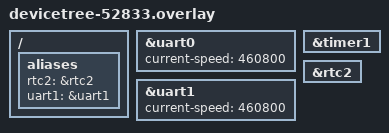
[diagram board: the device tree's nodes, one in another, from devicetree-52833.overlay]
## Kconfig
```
#
# Copyright (c) 2020 Nordic Semiconductor
#
# SPDX-License-Identifier: LicenseRef-Nordic-5-Clause
#

source "Kconfig.zephyr"

menu "Nordic Bluetooth Mesh chat client sample"

config DEVICE_IS_MASTER
    bool "Device is master"
    default n
    help
      Set to y if this device should act as the master device.
	  
config BT_MESH_CHAT_CLI_MESSAGE_LENGTH
	int "Max length of the message to be sent over mesh"
	default 90
	range 0 255
	help
	  Impacts on memory size occupied by the buffer of a message to be
	  published. This does not include null terminator. The message must also
	  fit into the application SDU. Adjust BT_MESH_TX_SEG_MAX and
	  BT_MESH_RX_SEG_MAX to be able to receive the longest messages.

config BT_MESH_CHAT_SAMPLE_PRESENCE_CACHE_SIZE
	int "Presence cache size"
	default 10
	range 0 32767
	help
	  Presence cache stores previously received presence of chat clients.
	  Recommended to be as big as number of chat clients in the mesh network.

config COUNTER_SAM0_TC32
	bool
	default y if BOARD_ATSAMD20_XPRO

endmenu

module = BT_MESH_CHAT_CLI
module-str = BT Mesh Chat Client model
source "${ZEPHYR_BASE}/subsys/logging/Kconfig.template.log_config"
```

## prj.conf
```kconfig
#
# Copyright (c) 2020 Nordic Semiconductor ASA
#
# SPDX-License-Identifier: LicenseRef-Nordic-5-Clause
#
CONFIG_NCS_SAMPLES_DEFAULTS=y

# Deffered logging helps improve LPN power consumption
# when friendship is established.
CONFIG_LOG_MODE_DEFERRED=y

# General configuration
CONFIG_SYSTEM_WORKQUEUE_STACK_SIZE=2048
CONFIG_FLASH=y
CONFIG_FLASH_MAP=y
CONFIG_NVS=y
CONFIG_SETTINGS=y
CONFIG_NVS_LOOKUP_CACHE=y
CONFIG_SETTINGS_NVS_NAME_CACHE=y
CONFIG_HWINFO=y
CONFIG_DK_LIBRARY=y
CONFIG_PM_SINGLE_IMAGE=y
CONFIG_PM_PARTITION_SIZE_SETTINGS_STORAGE=0x8000
CONFIG_SOC_FLASH_NRF_PARTIAL_ERASE=y

# Bluetooth configuration
CONFIG_BT=y
CONFIG_BT_DEVICE_NAME="Mesh Chat"
CONFIG_BT_L2CAP_TX_BUF_COUNT=8
CONFIG_BT_OBSERVER=y
CONFIG_BT_PERIPHERAL=y
CONFIG_BT_SETTINGS=y

# Disable unused Bluetooth features
CONFIG_BT_CTLR_LE_ENC=n
CONFIG_BT_PHY_UPDATE=n
CONFIG_BT_CTLR_CHAN_SEL_2=n
CONFIG_BT_CTLR_MIN_USED_CHAN=n
CONFIG_BT_CTLR_PRIVACY=n

# Bluetooth Mesh configuration
CONFIG_BT_MESH=y
CONFIG_BT_MESH_RELAY=y
CONFIG_BT_MESH_FRIEND=y
CONFIG_BT_MESH_RX_SEG_MAX=10
CONFIG_BT_MESH_TX_SEG_MAX=10
CONFIG_BT_MESH_PB_GATT=y
CONFIG_BT_MESH_GATT_PROXY=y
CONFIG_BT_MESH_DK_PROV=y

CONFIG_BT_MESH_TX_SEG_MSG_COUNT=5
CONFIG_BT_MESH_RX_SEG_MSG_COUNT=5
CONFIG_BT_MESH_CHAT_CLI_MESSAGE_LENGTH=70
CONFIG_BT_MESH_ADV_BUF_COUNT= 20
#CONFIG_BT_MESH_SEG_BUFS=1024


# Enable Bluetooth Mesh models debug logs
CONFIG_BT_MESH_LOG_LEVEL_ERR=y

# Enable Shell module and use UART as a backend
CONFIG_SHELL=y
CONFIG_SHELL_BACKEND_SERIAL=y
CONFIG_FLASH_SHELL=n
# Enable RTT for logging
CONFIG_USE_SEGGER_RTT=y
CONFIG_RTT_CONSOLE=y

# Enable logging
CONFIG_LOG=y
CONFIG_LOG_DEFAULT_LEVEL=3
CONFIG_LOG_BACKEND_RTT=y
CONFIG_LOG_BACKEND_UART=n

# Enable BT scan
CONFIG_BT_SCAN=y
# CONFIG_BT_SCAN_FILTER_ENABLE=y
CONFIG_BT_SCAN_UUID_CNT=20

CONFIG_BT_CTLR_TX_PWR_PLUS_8=y
```

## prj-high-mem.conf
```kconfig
# #
# # Copyright (c) 2020 Nordic Semiconductor ASA
# #
# # SPDX-License-Identifier: LicenseRef-Nordic-5-Clause
# #

# # MASTER device
# CONFIG_DEVICE_IS_MASTER=y

# CONFIG_NCS_SAMPLES_DEFAULTS=y

# # Deffered logging helps improve LPN power consumption
# # when friendship is established.
# CONFIG_LOG_MODE_DEFERRED=y

# # General configuration
# CONFIG_SYSTEM_WORKQUEUE_STACK_SIZE=2048
# CONFIG_FLASH=y
# CONFIG_FLASH_MAP=y
# CONFIG_NVS=y
# CONFIG_SETTINGS=y
# CONFIG_NVS_LOOKUP_CACHE=y
# CONFIG_SETTINGS_NVS_NAME_CACHE=y
# CONFIG_HWINFO=y
# CONFIG_DK_LIBRARY=y
# CONFIG_PM_SINGLE_IMAGE=y
# CONFIG_PM_PARTITION_SIZE_SETTINGS_STORAGE=0x8000
# CONFIG_SOC_FLASH_NRF_PARTIAL_ERASE=y

# # Bluetooth configuration
# CONFIG_BT=y
# CONFIG_BT_DEVICE_NAME="Mesh Chat"
# CONFIG_BT_L2CAP_TX_BUF_COUNT=8
# CONFIG_BT_OBSERVER=y
# CONFIG_BT_PERIPHERAL=y
# CONFIG_BT_SETTINGS=y
# CONFIG_BT_EXT_ADV=y

# # 5 sets are used by Bluetooth Mesh, 1 is needed for the sample advs.
# CONFIG_BT_EXT_ADV_MAX_ADV_SET=6
# CONFIG_BT_MAX_CONN=3
# CONFIG_BT_ID_MAX=2

# # Disable unused Bluetooth features
# # CONFIG_BT_CTLR_LE_ENC=n
# # CONFIG_BT_PHY_UPDATE=n
# # CONFIG_BT_CTLR_CHAN_SEL_2=n
# # CONFIG_BT_CTLR_MIN_USED_CHAN=n
# # CONFIG_BT_CTLR_PRIVACY=n

# # Bluetooth Mesh configuration
# CONFIG_BT_MESH=y
# CONFIG_BT_MESH_RELAY=y
# CONFIG_BT_MESH_FRIEND=y
# CONFIG_BT_MESH_RX_SEG_MAX=10
# CONFIG_BT_MESH_TX_SEG_MAX=10
# CONFIG_BT_MESH_PB_GATT=y
# CONFIG_BT_MESH_GATT_PROXY=y
# CONFIG_BT_MESH_DK_PROV=y
# CONFIG_BT_MESH_PB_ADV=y
# CONFIG_BT_MESH_CFG_CLI=y
# CONFIG_BT_MESH_MODEL_GROUP_COUNT=2

# # Enable Bluetooth Mesh models debug logs
# CONFIG_BT_MESH_LOG_LEVEL_DBG=y
# CONFIG_LOG=y
# CONFIG_LOG_DEFAULT_LEVEL=3
# CONFIG_UART_CONSOLE=n
# CONFIG_UART_LINE_CTRL=n


# # Enable Shell module and use UART as a backend
# CONFIG_SHELL=y
# CONFIG_SHELL_BACKEND_SERIAL=y
# CONFIG_FLASH_SHELL=n



# # RTT console 

# CONFIG_USE_SEGGER_RTT=y
# CONFIG_RTT_CONSOLE=y
# CONFIG_LOG_BACKEND_RTT=y
# CONFIG_LOG_BACKEND_UART=n
# CONFIG_SEGGER_RTT_MODE_NO_BLOCK_SKIP=y


# CONFIG_U_BT_NUS_CLIENT=y
# # CONFIG_BT_SCAN_FILTER_ENABLE=y
# # CONFIG_BT_GATT_DM=y
# # CONFIG_HEAP_MEM_POOL_SIZE=2048

# # # This example requires more stack
# # CONFIG_MAIN_STACK_SIZE=1536

# # # Enable bonding
# # CONFIG_FLASH_PAGE_LAYOUT=y

# # # Enable UART line control API
# # CONFIG_UART_LINE_CTRL=y
# # CONFIG_LOG_DEFAULT_LEVEL=4

# # CONFIG_ASSERT=y

# ART_INTERRUPT_DRIVEN=y
# CONFIG_COUNTER=y

# # Copyright (c) 2018 Nordic Semiconductor
# #
# # SPDX-License-Identifier: LicenseRef-Nordic-5-Clause
# #


# # Enable the BLE stack with GATT Client configuration
# CONFIG_BT_SMP=y
# CONFIG_BT_GATT_CLIENT=y

# # Enable the BLE modules from NCS
# CONFIG


#
# Copyright (c) 2020 Nordic Semiconductor ASA
#
# SPDX-License-Identifier: LicenseRef-Nordic-5-Clause
#

# # Enable the BLE modules from NCS
CONFIG_BT_SCAN=y
CONFIG_BT_SCAN_UUID_CNT=1
CONFIG_BT_MESH_LOW_POWER=n

# MASTER device
CONFIG_DEVICE_IS_MASTER=n

CONFIG_NCS_SAMPLES_DEFAULTS=y

# Deffered logging helps improve LPN power consumption
# when friendship is established.
CONFIG_LOG_MODE_DEFERRED=y

# General configuration
CONFIG_SYSTEM_WORKQUEUE_STACK_SIZE=2560
CONFIG_FLASH=y
CONFIG_FLASH_MAP=y
CONFIG_NVS=y
CONFIG_SETTINGS=y
CONFIG_NVS_LOOKUP_CACHE=y
CONFIG_SETTINGS_NVS_NAME_CACHE=y
CONFIG_HWINFO=y
CONFIG_DK_LIBRARY=y
CONFIG_PM_SINGLE_IMAGE=y
CONFIG_PM_PARTITION_SIZE_SETTINGS_STORAGE=0x8000
CONFIG_SOC_FLASH_NRF_PARTIAL_ERASE=y

# Bluetooth configuration
CONFIG_BT=y
CONFIG_BT_DEVICE_NAME="Mesh Chat"
CONFIG_BT_L2CAP_TX_BUF_COUNT=8
CONFIG_BT_OBSERVER=y
CONFIG_BT_PERIPHERAL=y
CONFIG_BT_SETTINGS=y

# Disable unused Bluetooth features
CONFIG_BT_CTLR_LE_ENC=n
CONFIG_BT_PHY_UPDATE=n
CONFIG_BT_CTLR_CHAN_SEL_2=n
CONFIG_BT_CTLR_MIN_USED_CHAN=n
CONFIG_BT_CTLR_PRIVACY=n

# Bluetooth Mesh configuration
CONFIG_BT_MESH=y
CONFIG_BT_MESH_RELAY=y
CONFIG_BT_MESH_FRIEND=y


# CONFIG_BT_MESH_RX_SEG_MAX=3
# CONFIG_BT_MESH_RX_SEG_MSG_COUNT=10
# CONFIG_BT_MESH_TX_SEG_MAX=3
# CONFIG_BT_MESH_TX_SEG_MSG_COUNT=10
# CONFIG_BT_MESH_CHAT_CLI_MESSAGE_LENGTH=25

# CONFIG_BT_MESH_ADV_BUF_COUNT=10
# CONFIG_BT_MESH_RELAY_BUF_COUNT=10

# Increase segmented message buffers
CONFIG_BT_MESH_TX_SEG_MSG_COUNT=32
CONFIG_BT_MESH_RX_SEG_MSG_COUNT=32
CONFIG_BT_MESH_RX_SEG_MAX=3
CONFIG_BT_MESH_TX_SEG_MAX=3

# Increase advertising and relay buffers
CONFIG_BT_MESH_ADV_BUF_COUNT=32
CONFIG_BT_MESH_RELAY_BUF_COUNT=32
CONFIG_BT_MESH_CHAT_CLI_MESSAGE_LENGTH=20

CONFIG_BT_MESH_PB_GATT=y
CONFIG_BT_MESH_GATT_PROXY=y
CONFIG_BT_MESH_DK_PROV=y

# Enable Bluetooth Mesh models debug logs
CONFIG_BT_MESH_LOG_LEVEL_DBG=y

# Enable Shell module and use UART as a backend
CONFIG_SHELL=y
CONFIG_SHELL_BACKEND_SERIAL=y
CONFIG_FLASH_SHELL=n

# Counter configuration
CONFIG_COUNTER=y
CONFIG_NRFX_RTC2=y

# Enable RTT for logging
CONFIG_USE_SEGGER_RTT=y
CONFIG_RTT_CONSOLE=y

# Enable logging
CONFIG_LOG=y
CONFIG_LOG_DEFAULT_LEVEL=3
CONFIG_LOG_BACKEND_RTT=y
CONFIG_LOG_BACKEND_UART=n

# Enable UART
CONFIG_SERIAL=y
CONFIG_UART_INTERRUPT_DRIVEN=y
# CONFIG_UART_ASYNC_API=y
CONFIG_UART_CONSOLE=y
CONFIG_UART_LINE_CTRL=y
```

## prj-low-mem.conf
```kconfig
# #
# # Copyright (c) 2020 Nordic Semiconductor ASA
# #
# # SPDX-License-Identifier: LicenseRef-Nordic-5-Clause
# #

# # MASTER device
# CONFIG_DEVICE_IS_MASTER=y

# CONFIG_NCS_SAMPLES_DEFAULTS=y

# # Deffered logging helps improve LPN power consumption
# # when friendship is established.
# CONFIG_LOG_MODE_DEFERRED=y

# # General configuration
# CONFIG_SYSTEM_WORKQUEUE_STACK_SIZE=2048
# CONFIG_FLASH=y
# CONFIG_FLASH_MAP=y
# CONFIG_NVS=y
# CONFIG_SETTINGS=y
# CONFIG_NVS_LOOKUP_CACHE=y
# CONFIG_SETTINGS_NVS_NAME_CACHE=y
# CONFIG_HWINFO=y
# CONFIG_DK_LIBRARY=y
# CONFIG_PM_SINGLE_IMAGE=y
# CONFIG_PM_PARTITION_SIZE_SETTINGS_STORAGE=0x8000
# CONFIG_SOC_FLASH_NRF_PARTIAL_ERASE=y

# # Bluetooth configuration
# CONFIG_BT=y
# CONFIG_BT_DEVICE_NAME="Mesh Chat"
# CONFIG_BT_L2CAP_TX_BUF_COUNT=8
# CONFIG_BT_OBSERVER=y
# CONFIG_BT_PERIPHERAL=y
# CONFIG_BT_SETTINGS=y
# CONFIG_BT_EXT_ADV=y

# # 5 sets are used by Bluetooth Mesh, 1 is needed for the sample advs.
# CONFIG_BT_EXT_ADV_MAX_ADV_SET=6
# CONFIG_BT_MAX_CONN=3
# CONFIG_BT_ID_MAX=2

# # Disable unused Bluetooth features
# # CONFIG_BT_CTLR_LE_ENC=n
# # CONFIG_BT_PHY_UPDATE=n
# # CONFIG_BT_CTLR_CHAN_SEL_2=n
# # CONFIG_BT_CTLR_MIN_USED_CHAN=n
# # CONFIG_BT_CTLR_PRIVACY=n

# # Bluetooth Mesh configuration
# CONFIG_BT_MESH=y
# CONFIG_BT_MESH_RELAY=y
# CONFIG_BT_MESH_FRIEND=y
# CONFIG_BT_MESH_RX_SEG_MAX=10
# CONFIG_BT_MESH_TX_SEG_MAX=10
# CONFIG_BT_MESH_PB_GATT=y
# CONFIG_BT_MESH_GATT_PROXY=y
# CONFIG_BT_MESH_DK_PROV=y
# CONFIG_BT_MESH_PB_ADV=y
# CONFIG_BT_MESH_CFG_CLI=y
# CONFIG_BT_MESH_MODEL_GROUP_COUNT=2

# # Enable Bluetooth Mesh models debug logs
# CONFIG_BT_MESH_LOG_LEVEL_DBG=y
# CONFIG_LOG=y
# CONFIG_LOG_DEFAULT_LEVEL=3
# CONFIG_UART_CONSOLE=n
# CONFIG_UART_LINE_CTRL=n


# # Enable Shell module and use UART as a backend
# CONFIG_SHELL=y
# CONFIG_SHELL_BACKEND_SERIAL=y
# CONFIG_FLASH_SHELL=n



# # RTT console 

# CONFIG_USE_SEGGER_RTT=y
# CONFIG_RTT_CONSOLE=y
# CONFIG_LOG_BACKEND_RTT=y
# CONFIG_LOG_BACKEND_UART=n
# CONFIG_SEGGER_RTT_MODE_NO_BLOCK_SKIP=y


# CONFIG_U_BT_NUS_CLIENT=y
# # CONFIG_BT_SCAN_FILTER_ENABLE=y
# # CONFIG_BT_GATT_DM=y
# # CONFIG_HEAP_MEM_POOL_SIZE=2048

# # # This example requires more stack
# # CONFIG_MAIN_STACK_SIZE=1536

# # # Enable bonding
# # CONFIG_FLASH_PAGE_LAYOUT=y

# # # Enable UART line control API
# # CONFIG_UART_LINE_CTRL=y
# # CONFIG_LOG_DEFAULT_LEVEL=4

# # CONFIG_ASSERT=y

# ART_INTERRUPT_DRIVEN=y
# CONFIG_COUNTER=y

# # Copyright (c) 2018 Nordic Semiconductor
# #
# # SPDX-License-Identifier: LicenseRef-Nordic-5-Clause
# #


# # Enable the BLE stack with GATT Client configuration
# CONFIG_BT_SMP=y
# CONFIG_BT_GATT_CLIENT=y

# # Enable the BLE modules from NCS
# CONFIG


#
# Copyright (c) 2020 Nordic Semiconductor ASA
#
# SPDX-License-Identifier: LicenseRef-Nordic-5-Clause
#

# # Enable the BLE modules from NCS
CONFIG_BT_SCAN=y
CONFIG_BT_SCAN_UUID_CNT=1
CONFIG_BT_MESH_LOW_POWER=n

# MASTER device
CONFIG_DEVICE_IS_MASTER=y

CONFIG_NCS_SAMPLES_DEFAULTS=y

# Deffered logging helps improve LPN power consumption
# when friendship is established.
CONFIG_LOG_MODE_DEFERRED=y

# General configuration
CONFIG_SYSTEM_WORKQUEUE_STACK_SIZE=2048
CONFIG_FLASH=y
CONFIG_FLASH_MAP=y
CONFIG_NVS=y
CONFIG_SETTINGS=y
CONFIG_NVS_LOOKUP_CACHE=y
CONFIG_SETTINGS_NVS_NAME_CACHE=y
CONFIG_HWINFO=y
CONFIG_DK_LIBRARY=y
CONFIG_PM_SINGLE_IMAGE=y
CONFIG_PM_PARTITION_SIZE_SETTINGS_STORAGE=0x8000
CONFIG_SOC_FLASH_NRF_PARTIAL_ERASE=y

# Bluetooth configuration
CONFIG_BT=y
CONFIG_BT_DEVICE_NAME="Mesh Chat"
CONFIG_BT_L2CAP_TX_BUF_COUNT=8
CONFIG_BT_OBSERVER=y
CONFIG_BT_PERIPHERAL=y
CONFIG_BT_SETTINGS=y

# Disable unused Bluetooth features
CONFIG_BT_CTLR_LE_ENC=n
CONFIG_BT_PHY_UPDATE=n
CONFIG_BT_CTLR_CHAN_SEL_2=n
CONFIG_BT_CTLR_MIN_USED_CHAN=n
CONFIG_BT_CTLR_PRIVACY=n

# Bluetooth Mesh configuration
CONFIG_BT_MESH=y
CONFIG_BT_MESH_RELAY=y
CONFIG_BT_MESH_FRIEND=y

# Increase segmented message buffers
CONFIG_BT_MESH_TX_SEG_MSG_COUNT=10
CONFIG_BT_MESH_RX_SEG_MSG_COUNT=10
CONFIG_BT_MESH_RX_SEG_MAX=3
CONFIG_BT_MESH_TX_SEG_MAX=3

# Increase advertising and relay buffers
CONFIG_BT_MESH_ADV_BUF_COUNT=20
CONFIG_BT_MESH_RELAY_BUF_COUNT=20
CONFIG_BT_MESH_CHAT_CLI_MESSAGE_LENGTH=20

CONFIG_BT_MESH_PB_GATT=y
CONFIG_BT_MESH_GATT_PROXY=y
CONFIG_BT_MESH_DK_PROV=y

# Enable Bluetooth Mesh models debug logs
CONFIG_BT_MESH_LOG_LEVEL_DBG=y

# Enable Shell module and use UART as a backend
CONFIG_SHELL=y
CONFIG_SHELL_BACKEND_SERIAL=y
CONFIG_FLASH_SHELL=n

# Counter configuration
CONFIG_COUNTER=y
CONFIG_NRFX_RTC2=y

# Enable RTT for logging
CONFIG_USE_SEGGER_RTT=y
CONFIG_RTT_CONSOLE=y

# Enable logging
CONFIG_LOG=y
CONFIG_LOG_DEFAULT_LEVEL=3
CONFIG_LOG_BACKEND_RTT=y
CONFIG_LOG_BACKEND_UART=n
CONFIG_UART_CONSOLE=n


# Enable UART
CONFIG_SERIAL=y
CONFIG_UART_LINE_CTRL=n
CONFIG_UART_INTERRUPT_DRIVEN=n
```

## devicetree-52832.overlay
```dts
&uart0 {
	current-speed = <460800>;
};

/ {
    aliases {
        rtc2 = &rtc2;
    };

    compatible = "nordic,nrf52-dk-nrf52832";
};

&timer1 {
    status = "okay";
};

&rtc2 {
    status = "okay";  // Use RTC2 instead of RTC1
};
```

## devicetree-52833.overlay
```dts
&uart0 {
	current-speed = <460800>;
};

/ {
    aliases {
        rtc2 = &rtc2;
        uart1 = &uart1;
    };
};

&timer1 {
    status = "okay";
};

&rtc2 {
    status = "okay";  // Use RTC2 instead of RTC1
};


&uart1 {
    status = "okay";
	current-speed = <460800>;
};
```

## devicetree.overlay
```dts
&uart0 {
	current-speed = <460800>;
};

/ {
    aliases {
        rtc2 = &rtc2;
    };
};

&timer1 {
    status = "okay";
};

&rtc2 {
    status = "okay";  // Use RTC2 instead of RTC1
};
```

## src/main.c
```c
/*
 * Copyright (c) 2019 Nordic Semiconductor ASA
 *
 * SPDX-License-Identifier: LicenseRef-Nordic-5-Clause
 */

/** @file
 *  @brief Nordic Mesh light sample
 */
#include <zephyr/bluetooth/bluetooth.h>
#include <bluetooth/mesh/models.h>
#include <bluetooth/mesh/dk_prov.h>
#include <dk_buttons_and_leds.h>
#include "model_handler.h"

#include <zephyr/logging/log.h>
LOG_MODULE_REGISTER(chat, CONFIG_LOG_DEFAULT_LEVEL);

static void bt_ready(int err)
{
	if (err) {
		printk("Bluetooth init failed (err %d)\n", err);
		return;
	}

	printk("Bluetooth initialized\n");

	dk_leds_init();
	dk_buttons_init(NULL);

	err = bt_mesh_init(bt_mesh_dk_prov_init(), model_handler_init());
	if (err) {
		printk("Initializing mesh failed (err %d)\n", err);
		return;
	}

	if (IS_ENABLED(CONFIG_SETTINGS)) {
		settings_load();
	}

	/* This will be a no-op if settings_load() loaded provisioning info */
	bt_mesh_prov_enable(BT_MESH_PROV_ADV | BT_MESH_PROV_GATT);

	printk("Mesh initialized\n");
}

int main(void)
{
	int err;

	printk("Initializing...\n");

	err = bt_enable(bt_ready);
	if (err) {
		printk("Bluetooth init failed (err %d)\n", err);
	}

    // Wait for provisioned.
	while (bt_mesh_is_provisioned() == false)
	{
		k_sleep(K_MSEC(100));
	}

	cmd_set_client_server_mode();
	cmd_scan_init();

	while (1)
	{
		//cmd_auto_message();
		k_sleep(K_MSEC(3000));
		cmd_send_update();
	}
	return 0;
}
```

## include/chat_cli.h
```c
/*
 * Copyright (c) 2020 Nordic Semiconductor ASA
 *
 * SPDX-License-Identifier: LicenseRef-Nordic-5-Clause
 */

/**
 * @file
 * @defgroup bt_mesh_chat_cli
 * @{
 * @brief API for the Bluetooth Mesh Chat Client model.
 */

#ifndef BT_MESH_CHAT_CLI_H__
#define BT_MESH_CHAT_CLI_H__

#include <zephyr/bluetooth/mesh.h>
#include <bluetooth/mesh/model_types.h>

#ifdef __cplusplus
extern "C" {
#endif

/* .. include_startingpoint_chat_cli_rst_1 */
/** Company ID of the Bluetooth Mesh Chat Client model. */
#define BT_MESH_CHAT_CLI_VENDOR_COMPANY_ID    CONFIG_BT_COMPANY_ID_NORDIC

/** Model ID of the Bluetooth Mesh Chat Client model. */
#define BT_MESH_CHAT_CLI_VENDOR_MODEL_ID      0x000A

/** Non-private message opcode. */
#define BT_MESH_CHAT_CLI_OP_MESSAGE BT_MESH_MODEL_OP_3(0x0A, \
				       BT_MESH_CHAT_CLI_VENDOR_COMPANY_ID)

/** Private message opcode. */
#define BT_MESH_CHAT_CLI_OP_PRIVATE_MESSAGE BT_MESH_MODEL_OP_3(0x0B, \
				       BT_MESH_CHAT_CLI_VENDOR_COMPANY_ID)

/** Message reply opcode. */
#define BT_MESH_CHAT_CLI_OP_MESSAGE_REPLY BT_MESH_MODEL_OP_3(0x0C, \
				       BT_MESH_CHAT_CLI_VENDOR_COMPANY_ID)

/** Presence message opcode. */
#define BT_MESH_CHAT_CLI_OP_PRESENCE BT_MESH_MODEL_OP_3(0x0D, \
				       BT_MESH_CHAT_CLI_VENDOR_COMPANY_ID)

/** Presence get message opcode. */
#define BT_MESH_CHAT_CLI_OP_PRESENCE_GET BT_MESH_MODEL_OP_3(0x0E, \
				       BT_MESH_CHAT_CLI_VENDOR_COMPANY_ID)
/* .. include_endpoint_chat_cli_rst_1 */

#define BT_MESH_CHAT_CLI_MSG_MINLEN_MESSAGE 1
#define BT_MESH_CHAT_CLI_MSG_MAXLEN_MESSAGE (\
				     CONFIG_BT_MESH_CHAT_CLI_MESSAGE_LENGTH \
				     + 1) /* + \0 */
#define BT_MESH_CHAT_CLI_MSG_LEN_MESSAGE_REPLY 0
#define BT_MESH_CHAT_CLI_MSG_LEN_PRESENCE 1
#define BT_MESH_CHAT_CLI_MSG_LEN_PRESENCE_GET 0

/** Bluetooth Mesh Chat Client Presence values. */
enum bt_mesh_chat_cli_presence {
	BT_MESH_CHAT_CLI_PRESENCE_AVAILABLE,
	BT_MESH_CHAT_CLI_PRESENCE_AWAY,
	BT_MESH_CHAT_CLI_PRESENCE_INACTIVE,
	BT_MESH_CHAT_CLI_PRESENCE_DO_NOT_DISTURB
};

/* Forward declaration of the Bluetooth Mesh Chat Client model context. */
struct bt_mesh_chat_cli;

/* .. include_startingpoint_chat_cli_rst_2 */
/** @def BT_MESH_MODEL_CHAT_CLI
 *
 * @brief Bluetooth Mesh Chat Client model composition data entry.
 *
 * @param[in] _chat Pointer to a @ref bt_mesh_chat_cli instance.
 */
#define BT_MESH_MODEL_CHAT_CLI(_chat)                                          \
		BT_MESH_MODEL_VND_CB(BT_MESH_CHAT_CLI_VENDOR_COMPANY_ID,       \
			BT_MESH_CHAT_CLI_VENDOR_MODEL_ID,                      \
			_bt_mesh_chat_cli_op, &(_chat)->pub,                   \
			BT_MESH_MODEL_USER_DATA(struct bt_mesh_chat_cli,       \
						_chat),                        \
			&_bt_mesh_chat_cli_cb)
/* .. include_endpoint_chat_cli_rst_2 */

/** Bluetooth Mesh Chat Client model handlers. */
struct bt_mesh_chat_cli_handlers {
	/** @brief Called after the node has been provisioned, or after all
	 * mesh data has been loaded from persistent storage.
	 *
	 * @param[in] cli Chat Client instance that has been started.
	 */
	void (*const start)(struct bt_mesh_chat_cli *chat);

	/** @brief Handler for a presence message.
	 *
	 * @param[in] cli Chat client instance that received the text message.
	 * @param[in] ctx Context of the incoming message.
	 * @param[in] presence Presence of a Chat Client that published
	 * the message.
	 */
	void (*const presence)(struct bt_mesh_chat_cli *chat,
			       struct bt_mesh_msg_ctx *ctx,
			       enum bt_mesh_chat_cli_presence presence);

	/** @brief Handler for a non-private text message.
	 *
	 * @param[in] cli Chat client instance that received the text message.
	 * @param[in] ctx Context of the incoming message.
	 * @param[in] msg Pointer to a received text message terminated with
	 * a null character, '\0'.
	 */
	void (*const message)(struct bt_mesh_chat_cli *chat,
			      struct bt_mesh_msg_ctx *ctx,
			      const uint8_t *msg);

	/** @brief Handler for a private message.
	 *
	 * @param[in] cli Chat client that received the text message.
	 * @param[in] ctx Context of the incoming message.
	 * @param[in] msg Pointer to a received text message terminated with
	 * a null character, '\0'.
	 */
	void (*const private_message)(struct bt_mesh_chat_cli *chat,
				      struct bt_mesh_msg_ctx *ctx,
				      const uint8_t *msg, uint16_t len);

	/** @brief Handler for a reply on a private message.
	 *
	 * @param[in] cli Chat client instance that received the reply.
	 * @param[in] ctx Context of the incoming message.
	 */
	void (*const message_reply)(struct bt_mesh_chat_cli *chat,
				    struct bt_mesh_msg_ctx *ctx);
};

/* .. include_startingpoint_chat_cli_rst_3 */
/**
 * Bluetooth Mesh Chat Client model context.
 */
struct bt_mesh_chat_cli {
	/** Access model pointer. */
	const struct bt_mesh_model *model;
	/** Publish parameters. */
	struct bt_mesh_model_pub pub;
	/** Publication message. */
	struct net_buf_simple pub_msg;
	/** Publication message buffer. */
	uint8_t buf[BT_MESH_MODEL_BUF_LEN(BT_MESH_CHAT_CLI_OP_MESSAGE,
					  BT_MESH_CHAT_CLI_MSG_MAXLEN_MESSAGE)];
	/** Handler function structure. */
	const struct bt_mesh_chat_cli_handlers *handlers;
	/** Current Presence value. */
	enum bt_mesh_chat_cli_presence presence;
};
/* .. include_endpoint_chat_cli_rst_3 */

/** @brief Set the client presence and publish the presence to the mesh network.
 *
 * @param[in] chat     Chat Client model instance to set presence on.
 * @param[in] presence Presence status to be published.
 *
 * @retval 0 Successfully set the preceive and sent the message.
 * @retval -EADDRNOTAVAIL Publishing is not configured.
 * @retval -EAGAIN The device has not been provisioned.
 */
int bt_mesh_chat_cli_presence_set(struct bt_mesh_chat_cli *chat,
				  enum bt_mesh_chat_cli_presence presence);

/** @brief Get current presence value of a chat client.
 *
 * @param[in] chat Chat Client model instance to send the message.
 * @param[in] addr Address of the chat client to get presence value of.
 *
 * @retval 0 Successfully sent the message.
 * @retval -EINVAL The model is not bound to an application key.
 * @retval -EAGAIN The device has not been provisioned.
 */
int bt_mesh_chat_cli_presence_get(struct bt_mesh_chat_cli *chat,
				  uint16_t addr);

/** @brief Send a text message.
 *
 * @param[in] cli Chat Client model instance to send the message.
 * @param[in] msg Pointer to a text message to send. Must be terminated with
 * a null character, '\0'.
 *
 * @retval 0 Successfully sent the message.
 * @retval -EADDRNOTAVAIL Publishing is not configured.
 * @retval -EAGAIN The device has not been provisioned.
 */
int bt_mesh_chat_cli_message_send(struct bt_mesh_chat_cli *chat,
				  const uint8_t *msg);

/** @brief Send a text message to a specified destination.
 *
 * @param[in] cli  Chat Client model instance to send the message.
 * @param[in] addr Address of the chat client to send message to.
 * @param[in] msg  Pointer to a text message to send. Must be terminated with
 * a null character, '\0'.
 *
 * @retval 0 Successfully sent the message.
 * @retval -EINVAL The model is not bound to an application key.
 * @retval -EAGAIN The device has not been provisioned.
 */
int bt_mesh_chat_cli_private_message_send(struct bt_mesh_chat_cli *chat,
					  uint16_t addr,
					  const uint8_t *msg);

int bt_mesh_chat_cli_private_message_send_binary(struct bt_mesh_chat_cli *chat,
					  uint16_t addr,
					  const uint8_t *msg, const uint8_t len);

/** @cond INTERNAL_HIDDEN */
extern const struct bt_mesh_model_op _bt_mesh_chat_cli_op[];
extern const struct bt_mesh_model_cb _bt_mesh_chat_cli_cb;
/** @endcond */

#ifdef __cplusplus
}
#endif

#endif /* BT_MESH_CHAT_CLI_H__ */

/** @} */
```

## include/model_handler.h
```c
/*
 * Copyright (c) 2020 Nordic Semiconductor ASA
 *
 * SPDX-License-Identifier: LicenseRef-Nordic-5-Clause
 */

/**
 * @file
 * @brief Model handler
 */

#ifndef MODEL_HANDLER_H__
#define MODEL_HANDLER_H__

#include <zephyr/bluetooth/mesh.h>

#ifdef __cplusplus
extern "C" {
#endif

const struct bt_mesh_comp *model_handler_init(void);

int  cmd_scan_init(void);
void cmd_set_client_server_mode(void);
void cmd_send_update(void);

#ifdef __cplusplus
}
#endif

#endif /* MODEL_HANDLER_H__ */
```

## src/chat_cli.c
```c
/*
 * Copyright (c) 2019 Nordic Semiconductor ASA
 *
 * SPDX-License-Identifier: LicenseRef-Nordic-5-Clause
 */

#include <zephyr/bluetooth/mesh.h>
#include "chat_cli.h"
#include "mesh/net.h"
#include <string.h>

#include <zephyr/logging/log.h>
LOG_MODULE_DECLARE(chat);

BUILD_ASSERT(BT_MESH_MODEL_BUF_LEN(BT_MESH_CHAT_CLI_OP_MESSAGE,
				   BT_MESH_CHAT_CLI_MSG_MAXLEN_MESSAGE) <=
		    BT_MESH_RX_SDU_MAX,
	     "The message must fit inside an application SDU.");
BUILD_ASSERT(BT_MESH_MODEL_BUF_LEN(BT_MESH_CHAT_CLI_OP_MESSAGE,
				   BT_MESH_CHAT_CLI_MSG_MAXLEN_MESSAGE) <=
		    BT_MESH_TX_SDU_MAX,
	     "The message must fit inside an application SDU.");

static void encode_presence(struct net_buf_simple *buf,
			    enum bt_mesh_chat_cli_presence presence)
{
	bt_mesh_model_msg_init(buf, BT_MESH_CHAT_CLI_OP_PRESENCE);
	net_buf_simple_add_u8(buf, presence);
}

static const uint8_t *extract_msg(struct net_buf_simple *buf)
{
	buf->data[buf->len - 1] = '\0';
	return net_buf_simple_pull_mem(buf, buf->len);
}

static int handle_message(const struct bt_mesh_model *model, struct bt_mesh_msg_ctx *ctx,
			  struct net_buf_simple *buf)
{
	struct bt_mesh_chat_cli *chat = model->rt->user_data;
	const uint8_t *msg;

	msg = extract_msg(buf);

	if (chat->handlers->message) {
		chat->handlers->message(chat, ctx, msg);
	}

	return 0;
}

/* .. include_startingpoint_chat_cli_rst_1 */
static void send_message_reply(struct bt_mesh_chat_cli *chat,
			     struct bt_mesh_msg_ctx *ctx)
{
	BT_MESH_MODEL_BUF_DEFINE(msg, BT_MESH_CHAT_CLI_OP_MESSAGE_REPLY,
				 BT_MESH_CHAT_CLI_MSG_LEN_MESSAGE_REPLY);
	bt_mesh_model_msg_init(&msg, BT_MESH_CHAT_CLI_OP_MESSAGE_REPLY);

	(void)bt_mesh_model_send(chat->model, ctx, &msg, NULL, NULL);
}

static int handle_private_message(const struct bt_mesh_model *model, struct bt_mesh_msg_ctx *ctx,
				  struct net_buf_simple *buf)
{
	struct bt_mesh_chat_cli *chat = model->rt->user_data;
	const uint8_t *msg;

	uint16_t len = buf->len;
	msg = net_buf_simple_pull_mem(buf, buf->len);

	if (chat->handlers->private_message) {
		chat->handlers->private_message(chat, ctx, msg, len);
	}

	send_message_reply(chat, ctx);
	return 0;
}
/* .. include_endpoint_chat_cli_rst_1 */

static int handle_message_reply(const struct bt_mesh_model *model, struct bt_mesh_msg_ctx *ctx,
				struct net_buf_simple *buf)
{
	struct bt_mesh_chat_cli *chat = model->rt->user_data;

	if (chat->handlers->message_reply) {
		chat->handlers->message_reply(chat, ctx);
	}

	return 0;
}

static int handle_presence(const struct bt_mesh_model *model, struct bt_mesh_msg_ctx *ctx,
			   struct net_buf_simple *buf)
{
	struct bt_mesh_chat_cli *chat = model->rt->user_data;
	enum bt_mesh_chat_cli_presence presence;

	presence = net_buf_simple_pull_u8(buf);

	if (chat->handlers->presence) {
		chat->handlers->presence(chat, ctx, presence);
	}

	return 0;
}

static int handle_presence_get(const struct bt_mesh_model *model, struct bt_mesh_msg_ctx *ctx,
			       struct net_buf_simple *buf)
{
	struct bt_mesh_chat_cli *chat = model->rt->user_data;

	BT_MESH_MODEL_BUF_DEFINE(msg, BT_MESH_CHAT_CLI_OP_PRESENCE,
				 BT_MESH_CHAT_CLI_MSG_LEN_PRESENCE);

	encode_presence(&msg, chat->presence);

	(void)bt_mesh_model_send(chat->model, ctx, &msg, NULL, NULL);

	return 0;
}

/* .. include_startingpoint_chat_cli_rst_2 */
const struct bt_mesh_model_op _bt_mesh_chat_cli_op[] = {
	{
		BT_MESH_CHAT_CLI_OP_MESSAGE,
		BT_MESH_LEN_MIN(BT_MESH_CHAT_CLI_MSG_MINLEN_MESSAGE),
		handle_message
	},
	{
		BT_MESH_CHAT_CLI_OP_PRIVATE_MESSAGE,
		BT_MESH_LEN_MIN(BT_MESH_CHAT_CLI_MSG_MINLEN_MESSAGE),
		handle_private_message
	},
	{
		BT_MESH_CHAT_CLI_OP_MESSAGE_REPLY,
		BT_MESH_LEN_EXACT(BT_MESH_CHAT_CLI_MSG_LEN_MESSAGE_REPLY),
		handle_message_reply
	},
	{
		BT_MESH_CHAT_CLI_OP_PRESENCE,
		BT_MESH_LEN_EXACT(BT_MESH_CHAT_CLI_MSG_LEN_PRESENCE),
		handle_presence
	},
	{
		BT_MESH_CHAT_CLI_OP_PRESENCE_GET,
		BT_MESH_LEN_EXACT(BT_MESH_CHAT_CLI_MSG_LEN_PRESENCE_GET),
		handle_presence_get
	},
	BT_MESH_MODEL_OP_END,
};
/* .. include_endpoint_chat_cli_rst_2 */

static int bt_mesh_chat_cli_update_handler(const struct bt_mesh_model *model)
{
	struct bt_mesh_chat_cli *chat = model->rt->user_data;

	/* Continue publishing current presence. */
	encode_presence(model->pub->msg, chat->presence);

	return 0;
}

/* .. include_startingpoint_chat_cli_rst_3 */
#ifdef CONFIG_BT_SETTINGS
static int bt_mesh_chat_cli_settings_set(const struct bt_mesh_model *model,
					 const char *name,
					 size_t len_rd,
					 settings_read_cb read_cb,
					 void *cb_arg)
{
	struct bt_mesh_chat_cli *chat = model->rt->user_data;

	if (name) {
		return -ENOENT;
	}

	ssize_t bytes = read_cb(cb_arg, &chat->presence,
				sizeof(chat->presence));
	if (bytes < 0) {
		return bytes;
	}

	if (bytes != 0 && bytes != sizeof(chat->presence)) {
		return -EINVAL;
	}

	return 0;
}
#endif
/* .. include_endpoint_chat_cli_rst_3 */

/* .. include_startingpoint_chat_cli_rst_4 */
static int bt_mesh_chat_cli_init(const struct bt_mesh_model *model)
{
	struct bt_mesh_chat_cli *chat = model->rt->user_data;

	chat->model = model;

	net_buf_simple_init_with_data(&chat->pub_msg, chat->buf,
				      sizeof(chat->buf));
	chat->pub.msg = &chat->pub_msg;
	chat->pub.update = bt_mesh_chat_cli_update_handler;

	return 0;
}
/* .. include_endpoint_chat_cli_rst_4 */

/* .. include_startingpoint_chat_cli_rst_5 */
static int bt_mesh_chat_cli_start(const struct bt_mesh_model *model)
{
	struct bt_mesh_chat_cli *chat = model->rt->user_data;

	if (chat->handlers->start) {
		chat->handlers->start(chat);
	}

	return 0;
}
/* .. include_endpoint_chat_cli_rst_5 */

/* .. include_startingpoint_chat_cli_rst_6 */
static void bt_mesh_chat_cli_reset(const struct bt_mesh_model *model)
{
	struct bt_mesh_chat_cli *chat = model->rt->user_data;

	chat->presence = BT_MESH_CHAT_CLI_PRESENCE_AVAILABLE;

	if (IS_ENABLED(CONFIG_BT_SETTINGS)) {
		(void) bt_mesh_model_data_store(model, true, NULL, NULL, 0);
	}
}
/* .. include_endpoint_chat_cli_rst_6 */

/* .. include_startingpoint_chat_cli_rst_7 */
const struct bt_mesh_model_cb _bt_mesh_chat_cli_cb = {
	.init = bt_mesh_chat_cli_init,
	.start = bt_mesh_chat_cli_start,
#ifdef CONFIG_BT_SETTINGS
	.settings_set = bt_mesh_chat_cli_settings_set,
#endif
	.reset = bt_mesh_chat_cli_reset,
};
/* .. include_endpoint_chat_cli_rst_7 */

/* .. include_startingpoint_chat_cli_rst_8 */
int bt_mesh_chat_cli_presence_set(struct bt_mesh_chat_cli *chat,
			 enum bt_mesh_chat_cli_presence presence)
{
	if (presence != chat->presence) {
		chat->presence = presence;

		if (IS_ENABLED(CONFIG_BT_SETTINGS)) {
			(void) bt_mesh_model_data_store(chat->model, true,
						NULL, &presence,
						sizeof(chat->presence));
		}
	}

	encode_presence(chat->model->pub->msg, chat->presence);

	return bt_mesh_model_publish(chat->model);
}
/* .. include_endpoint_chat_cli_rst_8 */

int bt_mesh_chat_cli_presence_get(struct bt_mesh_chat_cli *chat,
				  uint16_t addr)
{
	struct bt_mesh_msg_ctx ctx = {
		.addr = addr,
		.app_idx = chat->model->keys[0],
		.send_ttl = BT_MESH_TTL_DEFAULT,
		.send_rel = true,
	};

	BT_MESH_MODEL_BUF_DEFINE(buf, BT_MESH_CHAT_CLI_OP_PRESENCE_GET,
				 BT_MESH_CHAT_CLI_MSG_LEN_PRESENCE_GET);
	bt_mesh_model_msg_init(&buf, BT_MESH_CHAT_CLI_OP_PRESENCE_GET);

	return bt_mesh_model_send(chat->model, &ctx, &buf, NULL, NULL);
}

int bt_mesh_chat_cli_message_send(struct bt_mesh_chat_cli *chat,
				  const uint8_t *msg)
{
	struct net_buf_simple *buf = chat->model->pub->msg;

	bt_mesh_model_msg_init(buf, BT_MESH_CHAT_CLI_OP_MESSAGE);

	net_buf_simple_add_mem(buf, msg,
			       strnlen(msg,
				       CONFIG_BT_MESH_CHAT_CLI_MESSAGE_LENGTH));
	net_buf_simple_add_u8(buf, '\0');

	return bt_mesh_model_publish(chat->model);
}

/* .. include_startingpoint_chat_cli_rst_9 */
int bt_mesh_chat_cli_private_message_send(struct bt_mesh_chat_cli *chat,
					  uint16_t addr,
					  const uint8_t *msg)
{
	struct bt_mesh_msg_ctx ctx = {
		.addr = addr,
		.app_idx = chat->model->keys[0],
		.send_ttl = BT_MESH_TTL_DEFAULT,
		.send_rel = true,
	};

	BT_MESH_MODEL_BUF_DEFINE(buf, BT_MESH_CHAT_CLI_OP_PRIVATE_MESSAGE,
				 BT_MESH_CHAT_CLI_MSG_MAXLEN_MESSAGE);
	bt_mesh_model_msg_init(&buf, BT_MESH_CHAT_CLI_OP_PRIVATE_MESSAGE);

	net_buf_simple_add_mem(&buf, msg,
			       strnlen(msg,
				       CONFIG_BT_MESH_CHAT_CLI_MESSAGE_LENGTH));
	net_buf_simple_add_u8(&buf, '\0');

	return bt_mesh_model_send(chat->model, &ctx, &buf, NULL, NULL);
}

int bt_mesh_chat_cli_private_message_send_binary(struct bt_mesh_chat_cli *chat,
					  uint16_t addr,
					  const uint8_t *msg, const uint8_t len)
{
	struct bt_mesh_msg_ctx ctx = {
		.addr = addr,
		.app_idx = chat->model->keys[0],
		.send_ttl = BT_MESH_TTL_DEFAULT,
		.send_rel = true,
	};

	BT_MESH_MODEL_BUF_DEFINE(buf, BT_MESH_CHAT_CLI_OP_PRIVATE_MESSAGE,
				 BT_MESH_CHAT_CLI_MSG_MAXLEN_MESSAGE);
	bt_mesh_model_msg_init(&buf, BT_MESH_CHAT_CLI_OP_PRIVATE_MESSAGE);

	if(len > CONFIG_BT_MESH_CHAT_CLI_MESSAGE_LENGTH)
		LOG_ERR("Message len too large - %d", len);
	else
		net_buf_simple_add_mem(&buf, msg, len);

	return bt_mesh_model_send(chat->model, &ctx, &buf, NULL, NULL);
}
/* .. include_endpoint_chat_cli_rst_9 */
```

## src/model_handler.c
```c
/*
 * Copyright (c) 2019 Nordic Semiconductor ASA
 *
 * SPDX-License-Identifier: LicenseRef-Nordic-5-Clause
 */

#include <stdio.h>
#include <stdlib.h>

#include <zephyr/bluetooth/bluetooth.h>
#include <bluetooth/mesh/models.h>
#include <dk_buttons_and_leds.h>

#include <zephyr/shell/shell.h>
#include <zephyr/shell/shell_uart.h>

#include "chat_cli.h"
#include "model_handler.h"

#include <bluetooth/scan.h>

#include <zephyr/logging/log.h>
LOG_MODULE_DECLARE(chat);

void parse_binary_message (uint16_t addr, uint8_t *packet, char* prefix_str, uint16_t len);

static const struct shell *chat_shell;

/******************************************************************************/
/*************************** Health server setup ******************************/
/******************************************************************************/
/* Set up a repeating delayed work to blink the DK's LEDs when attention is
 * requested.
 */
static struct k_work_delayable attention_blink_work;
static bool attention;

static void attention_blink(struct k_work *work)
{
	static int idx;
	const uint8_t pattern[] = {
		BIT(0) | BIT(1),
		BIT(1) | BIT(2),
		BIT(2) | BIT(3),
		BIT(3) | BIT(0),
	};

	if (attention) {
		dk_set_leds(pattern[idx++ % ARRAY_SIZE(pattern)]);
		k_work_reschedule(&attention_blink_work, K_MSEC(30));
	} else {
		dk_set_leds(DK_NO_LEDS_MSK);
	}
}

static void attention_on(const struct bt_mesh_model *mod)
{
	attention = true;
	k_work_reschedule(&attention_blink_work, K_NO_WAIT);
}

static void attention_off(const struct bt_mesh_model *mod)
{
	/* Will stop rescheduling blink timer */
	attention = false;
}

static const struct bt_mesh_health_srv_cb health_srv_cb = {
	.attn_on = attention_on,
	.attn_off = attention_off,
};

static struct bt_mesh_health_srv health_srv = {
	.cb = &health_srv_cb,
};

BT_MESH_HEALTH_PUB_DEFINE(health_pub, 0);

/******************************************************************************/
/***************************** Chat model setup *******************************/
/******************************************************************************/
struct presence_cache {
	uint16_t addr;
	enum bt_mesh_chat_cli_presence presence;
};

/* Cache of Presence values of other chat clients. */
static struct presence_cache presence_cache[
			    CONFIG_BT_MESH_CHAT_SAMPLE_PRESENCE_CACHE_SIZE];

static const uint8_t *presence_string[] = {
	[BT_MESH_CHAT_CLI_PRESENCE_AVAILABLE] = "available",
	[BT_MESH_CHAT_CLI_PRESENCE_AWAY] = "away",
	[BT_MESH_CHAT_CLI_PRESENCE_DO_NOT_DISTURB] = "dnd",
	[BT_MESH_CHAT_CLI_PRESENCE_INACTIVE] = "inactive",
};

/**
 * Returns true if the specified address is an address of the local element.
 */
static bool address_is_local(const struct bt_mesh_model *mod, uint16_t addr)
{
	uint16_t local = bt_mesh_model_elem(mod)->rt->addr;

	return local == addr;
}

/**
 * Returns true if the provided address is unicast address.
 */
static bool address_is_unicast(uint16_t addr)
{
	return (addr > 0) && (addr <= 0x7FFF);
}

/**
 * Returns true if the node is new or the presence status is different from
 * the one stored in the cache.
 */
static bool presence_cache_entry_check_and_update(uint16_t addr,
				       enum bt_mesh_chat_cli_presence presence)
{
	static size_t presence_cache_head;
	size_t i;

	/* Find address in cache. */
	for (i = 0; i < ARRAY_SIZE(presence_cache); i++) {
		if (presence_cache[i].addr == addr) {
			if (presence_cache[i].presence == presence) {
				return false;
			}

			/* Break since the node in the cache. */
			break;
		}
	}

	/* Not in cache. */
	if (i == ARRAY_SIZE(presence_cache)) {
		for (i = 0; i < ARRAY_SIZE(presence_cache); i++) {
			if (!presence_cache[i].addr) {
				break;
			}
		}

		/* Cache is full. */
		if (i == ARRAY_SIZE(presence_cache)) {
			i = presence_cache_head;
			presence_cache_head = (presence_cache_head + 1)
			% CONFIG_BT_MESH_CHAT_SAMPLE_PRESENCE_CACHE_SIZE;
		}
	}

	/* Update cache. */
	presence_cache[i].addr = addr;
	presence_cache[i].presence = presence;

	return true;
}

static void print_client_status(void);

static void handle_chat_start(struct bt_mesh_chat_cli *chat)
{
	print_client_status();
}

static void handle_chat_presence(struct bt_mesh_chat_cli *chat,
				 struct bt_mesh_msg_ctx *ctx,
				 enum bt_mesh_chat_cli_presence presence)
{
	if (address_is_local(chat->model, ctx->addr)) {
		if (address_is_unicast(ctx->recv_dst)) {
			shell_print(chat_shell, "<you> are %s",
				    presence_string[presence]);
		}
	} else {
		if (address_is_unicast(ctx->recv_dst)) {
			shell_print(chat_shell, "<0x%04X> is %s", ctx->addr,
				    presence_string[presence]);
		} else if (presence_cache_entry_check_and_update(ctx->addr,
								 presence)) {
			shell_print(chat_shell, "<0x%04X> is now %s",
				    ctx->addr,
				    presence_string[presence]);
		}
	}
}

static void handle_chat_message(struct bt_mesh_chat_cli *chat,
				struct bt_mesh_msg_ctx *ctx,
				const uint8_t *msg)
{
	/* Don't print own messages. */
	if (address_is_local(chat->model, ctx->addr)) {
		return;
	}

	shell_print(chat_shell, "<0x%04X>: %s", ctx->addr, msg);
}

static void handle_chat_private_message(struct bt_mesh_chat_cli *chat,
					struct bt_mesh_msg_ctx *ctx,
					const uint8_t *msg, uint16_t len)
{
	/* Don't print own messages. */
//	if (address_is_local(chat->model, ctx->addr)) {
//		return;
//	}

	// parse and print
	parse_binary_message(ctx->addr, msg, "RCV", len);
	//shell_print(chat_shell, "<0x%04X>: *you* %s", ctx->addr, msg);

    static uint8_t state = 0;
	state++;
	dk_set_led(DK_LED2, state & 1);

}

static uint8_t received_flag = 0;

static void handle_chat_message_reply(struct bt_mesh_chat_cli *chat,
				      struct bt_mesh_msg_ctx *ctx)
{
	if (received_flag)
		received_flag--;
	//LOG_WRN("<0x%04X> received the message", ctx->addr);

	static uint8_t state = 0;
	state++;
	dk_set_led(DK_LED1, state & 1);
}

static const struct bt_mesh_chat_cli_handlers chat_handlers = {
	.start = handle_chat_start,
	.presence = handle_chat_presence,
	.message = handle_chat_message,
	.private_message = handle_chat_private_message,
	.message_reply = handle_chat_message_reply,
};

/* .. include_startingpoint_model_handler_rst_1 */
static struct bt_mesh_chat_cli chat = {
	.handlers = &chat_handlers,
};

static struct bt_mesh_elem elements[] = {
	BT_MESH_ELEM(
		1,
		BT_MESH_MODEL_LIST(
			BT_MESH_MODEL_CFG_SRV,
			BT_MESH_MODEL_HEALTH_SRV(&health_srv, &health_pub)),
		BT_MESH_MODEL_LIST(BT_MESH_MODEL_CHAT_CLI(&chat))),
};
/* .. include_endpoint_model_handler_rst_1 */

static void print_client_status(void)
{
	if (!bt_mesh_is_provisioned()) {
		shell_print(chat_shell,
			    "The mesh node is not provisioned. Please provision the mesh node before using the chat.");
	} else {
		shell_print(chat_shell,
			    "The mesh node is provisioned. The client address is 0x%04x.",
			    bt_mesh_model_elem(chat.model)->rt->addr);
	}

	shell_print(chat_shell, "Current presence: %s",
		    presence_string[chat.presence]);
}

static const struct bt_mesh_comp comp = {
	.cid = CONFIG_BT_COMPANY_ID,
	.elem = elements,
	.elem_count = ARRAY_SIZE(elements),
};

/******************************************************************************/
/******************************** Chat shell **********************************/
/******************************************************************************/
static int cmd_status(const struct shell *shell, size_t argc, char *argv[])
{
	print_client_status();

	return 0;
}

static int cmd_message(const struct shell *shell, size_t argc, char *argv[])
{
	int err;

	if (argc < 2) {
		return -EINVAL;
	}

	err = bt_mesh_chat_cli_message_send(&chat, argv[1]);
	if (err) {
		LOG_WRN("Failed to send message: %d", err);
	}

	/* Print own messages in the chat. */
	shell_print(shell, "<you>: %s", argv[1]);

	return 0;
}

/* *************  POC CODE STARTS HERE  *********************  */
#define MAX_DEVICES 20
#define NUM_OF_DEVICES_TO_SEND   10
#define SERVER_ADDR    0x99

struct __attribute__((packed, aligned(1))) device_info
{
    uint16_t addr;
    int8_t rssi;
    uint16_t last_seen;
};

struct __attribute__((packed, aligned(1))) packet_s
{
	uint16_t timestamp;
	struct device_info top_devices[NUM_OF_DEVICES_TO_SEND];
};

static struct device_info device_list[MAX_DEVICES] = {0};
static bool is_server = false;

void update_device_info(uint16_t addr, int8_t rssi, uint16_t last_seen)
{
    int empty_index = -1;
    int oldest_index = 0;
	int selected_index = INT_MAX;

	rssi = abs(rssi);

    // First loop: search for the device, store the index of the first empty slot, and track the oldest entry
    for (int i = 0; i < MAX_DEVICES; i++)
	{
        if (device_list[i].addr == addr)
		{
            // Device found, update it
            device_list[i].rssi = rssi;
            device_list[i].last_seen = last_seen;
			selected_index = i;
			break;
        }
	
        // Store the first empty slot index
		if (empty_index == -1 && device_list[i].addr == 0)
            empty_index = i;

        // Track the oldest entry
        if (device_list[i].last_seen < device_list[oldest_index].last_seen)
            oldest_index = i;
    }

	if (selected_index == INT_MAX)
	{
		// If the device was not found, add it to the first empty slot, if available
		if (empty_index != -1) {
			device_list[empty_index].addr =  addr;
			device_list[empty_index].rssi = rssi;
			device_list[empty_index].last_seen = last_seen;
			selected_index = empty_index;
			//shell_print(chat_shell, "Add empty to %d", empty_index);
		}
		else
		{
			// If the list is full, replace the oldest device
			device_list[oldest_index].addr = addr;
			device_list[oldest_index].rssi = rssi;
			device_list[oldest_index].last_seen = last_seen;
			//shell_print(chat_shell, "replace at %d", oldest_index);
			selected_index = oldest_index;
		}
	}

	if (!is_server)
		shell_print(chat_shell, "[%05d] - [%02d] %04X %d", last_seen, selected_index, addr, rssi);
}

int compare_devices(const void *a, const void *b) {
    struct device_info *device_a = (struct device_info *)a;
    struct device_info *device_b = (struct device_info *)b;

    return (device_b->last_seen - device_a->last_seen);
}

void get_top_devices(struct device_info *top_list, int top_count)
{
    // Make a copy of the original list
    struct device_info sorted_list[MAX_DEVICES];
    memcpy(sorted_list, device_list, sizeof(device_list));

    // Sort the copied list based on `last_seen`
    qsort(sorted_list, MAX_DEVICES, sizeof(struct device_info), compare_devices);

    // Copy the top X elements to the output list
    for (int i = 0; i < top_count && i < MAX_DEVICES; i++) {
        top_list[i].addr = sorted_list[i].addr;
        top_list[i].rssi = sorted_list[i].rssi;
        top_list[i].last_seen = sorted_list[i].last_seen;
    }
}

void get_device_info_string(struct device_info* info, char* str)
{
	// addr, rssi, last_seen
	sprintf (str, "%04X,%03d,%05d,", info->addr, (uint8_t)abs(info->rssi), info->last_seen);
}


void scan_filter_match(struct bt_scan_device_info *device_info,
		       struct bt_scan_filter_match *filter_match,
		       bool connectable)
{
	char addr[BT_ADDR_LE_STR_LEN];

	bt_addr_le_to_str(device_info->recv_info->addr, addr, sizeof(addr));

	shell_print(chat_shell, "Match. %s", addr);
}

void scan_filter_no_match(struct bt_scan_device_info *device_info,
			  bool connectable)
{
	uint8_t *addr = (uint8_t*)&device_info->recv_info->addr->a.val;

	if ((addr[5] == 0xC3) && (addr[4] == 0x00))
	{
		//shell_print(chat_shell, "%2X %2X %2X", addr[2], addr[1], addr[0]);
		uint16_t uptime = (uint16_t)(k_uptime_get() / 1000);
		uint16_t addr16 = (uint16_t)addr[1]*256 + addr[0];
		update_device_info(addr16, device_info->recv_info->rssi,  uptime);
	}

}

void cmd_send_update(void)
{
	static struct packet_s msg = {0};

	msg.timestamp = (uint16_t)(k_uptime_get() / 1000);
	get_top_devices(&msg.top_devices, NUM_OF_DEVICES_TO_SEND);

	if (!is_server)
	{
		// send the data to the server.
		bt_mesh_chat_cli_private_message_send_binary(&chat, SERVER_ADDR, (uint8_t*)&msg, sizeof(struct packet_s));
		parse_binary_message(bt_mesh_model_elem(chat.model)->rt->addr, (uint8_t*)&msg, "SND", sizeof(struct packet_s));
	}
	else
	{
		// send the data to the shell. no need to send it via the mesh.
		parse_binary_message(bt_mesh_model_elem(chat.model)->rt->addr, (uint8_t*)&msg, "RCV", sizeof(struct packet_s));
	}
}

void parse_binary_message (uint16_t addr, uint8_t *packet, char* prefix_str, uint16_t len)
{
	struct packet_s* data = (struct packet_s*)packet;
	char str[250];
	uint8_t str_index = 0;
	uint8_t num_devices = (len - 2) / sizeof(struct device_info);

	for (int i=0; i<num_devices; i++)
	{
		get_device_info_string(&data->top_devices[i], &str[str_index]);
		str_index = strlen(str);
	}

    // Remove the last comma.
	str[str_index-1] = '\0';
	
	shell_print(chat_shell, "[%05d] %s %04X,%05d,%s", (uint16_t)(k_uptime_get() / 1000), prefix_str, addr, data->timestamp, str);
}

BT_SCAN_CB_INIT(scan_cb, scan_filter_match, scan_filter_no_match, NULL, NULL);
static struct bt_le_scan_param scan_param = {
	.type = BT_LE_SCAN_TYPE_PASSIVE,
	.options = BT_LE_SCAN_OPT_FILTER_DUPLICATE,
	.interval = BT_GAP_SCAN_FAST_INTERVAL,
	.window = BT_GAP_SCAN_FAST_WINDOW,
};

static struct bt_scan_init_param scan_init = {
	.scan_param = &scan_param,
	.conn_param = NULL,
};

int cmd_scan_init(void)
{
	int err;

	bt_scan_init(&scan_init);
	bt_scan_cb_register(&scan_cb);
/*
	err = bt_scan_filter_add(BT_SCAN_FILTER_TYPE_UUID, BT_UUID_NUS_SERVICE);
	if (err) {
		LOG_ERR("Scanning filters cannot be set (err %d)", err);
		return err;
	}

	err = bt_scan_filter_enable(BT_SCAN_UUID_FILTER, false);
	if (err) {
		LOG_ERR("Filters cannot be turned on (err %d)", err);
		return err;
	}
*/
	LOG_INF("Scan module initialized");
	return err;
}

void cmd_set_client_server_mode(void)
{
	if (address_is_local(chat.model, SERVER_ADDR))
	{
		is_server = true;
	}

	shell_print(chat_shell, "****** MY ADDR IS %X  VER 1.0 ******", bt_mesh_model_elem(chat.model)->rt->addr);
}

static int cmd_private_message(const struct shell *shell, size_t argc,
			       char *argv[]) 
{
	uint16_t addr;
	int err;

	if (argc < 3) {
		return -EINVAL;
	}

	addr = strtol(argv[1], NULL, 0);

	/* Print own message to the chat. */
	shell_print(shell, "<you>: *0x%04X* %s", addr, argv[2]);

	err = bt_mesh_chat_cli_private_message_send(&chat, addr, argv[2]);
	if (err) {
		LOG_WRN("Failed to publish message: %d", err);
	}

	return 0;
}

static int cmd_presence_set(const struct shell *shell, size_t argc,
			    char *argv[])
{
	size_t i;

	if (argc < 2) {
		return -EINVAL;
	}

	for (i = 0; i < ARRAY_SIZE(presence_string); i++) {
		if (!strcmp(argv[1], presence_string[i])) {
			enum bt_mesh_chat_cli_presence presence;
			int err;

			presence = i;

			err = bt_mesh_chat_cli_presence_set(&chat, presence);
			if (err) {
				LOG_WRN("Failed to update presence: %d", err);
			}

			/* Print own presence in the chat. */
			shell_print(shell, "You are now %s",
				    presence_string[presence]);

			return 0;
		}
	}

	shell_print(shell,
		    "Unknown presence status: %s. Possible presence statuses:",
		    argv[1]);
	for (i = 0; i < ARRAY_SIZE(presence_string); i++) {
		shell_print(shell, "%s", presence_string[i]);
	}

	return 0;
}

static int cmd_presence_get(const struct shell *shell, size_t argc,
			    char *argv[])
{
	uint16_t addr;
	int err;

	if (argc < 2) {
		return -EINVAL;
	}

	addr = strtol(argv[1], NULL, 0);

	err = bt_mesh_chat_cli_presence_get(&chat, addr);
	if (err) {
		LOG_WRN("Failed to publish message: %d", err);
	}

	return 0;
}

SHELL_STATIC_SUBCMD_SET_CREATE(presence_cmds,
	SHELL_CMD_ARG(set, NULL,
		      "Set presence of the current client <presence: available, away, dnd or inactive>",
		      cmd_presence_set, 2, 0),
	SHELL_CMD_ARG(get, NULL,
		      "Get presence status of the remote node <node>",
		      cmd_presence_get, 2, 0),
	SHELL_SUBCMD_SET_END
);

static int cmd_presence(const struct shell *shell, size_t argc, char *argv[])
{
	if (argc == 1) {
		shell_help(shell);
		/* shell returns 1 when help is printed */
		return 1;
	}

	if (argc != 3) {
		return -EINVAL;
	}

	return 0;
}

SHELL_STATIC_SUBCMD_SET_CREATE(chat_cmds,
	SHELL_CMD_ARG(status, NULL, "Print client status", cmd_status, 1, 0),
	SHELL_CMD(presence, &presence_cmds, "Presence commands", cmd_presence),
	SHELL_CMD_ARG(private, NULL,
		      "Send a private text message to a client <node> <message>",
		      cmd_private_message, 3, 0),
	SHELL_CMD_ARG(msg, NULL, "Send a text message to the chat <message>",
		      cmd_message, 2, 0),
	SHELL_SUBCMD_SET_END
);

static int cmd_chat(const struct shell *shell, size_t argc, char **argv)
{
	if (argc == 1) {
		shell_help(shell);
		/* shell returns 1 when help is printed */
		return 1;
	}

	shell_error(shell, "%s unknown parameter: %s", argv[0], argv[1]);

	return -EINVAL;
}

SHELL_CMD_ARG_REGISTER(chat, &chat_cmds, "Bluetooth Mesh Chat Client commands",
		       cmd_chat, 1, 1);

/******************************************************************************/
/******************************** Public API **********************************/
/******************************************************************************/
const struct bt_mesh_comp *model_handler_init(void)
{
	k_work_init_delayable(&attention_blink_work, attention_blink);

	chat_shell = shell_backend_uart_get_ptr();
	shell_print(chat_shell, ">>> Bluetooth Mesh Chat sample <<<");
	
	return &comp;
}
```
